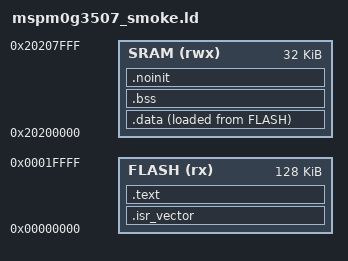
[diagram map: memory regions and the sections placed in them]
MEMORY
{
    FLASH (rx)  : ORIGIN = 0x00000000, LENGTH = 128K
    SRAM  (rwx) : ORIGIN = 0x20200000, LENGTH = 32K
}

_estack = ORIGIN(SRAM) + LENGTH(SRAM);

SECTIONS
{
    .isr_vector :
    {
        KEEP(*(.isr_vector))
    } > FLASH

    .text :
    {
        *(.text*)
        *(.rodata*)
        . = ALIGN(4);
    } > FLASH

    .data :
    {
        . = ALIGN(4);
        _sdata = .;
        *(.data*)
        . = ALIGN(4);
        _edata = .;
    } > SRAM AT > FLASH

    _sidata = LOADADDR(.data);

    .bss (NOLOAD) :
    {
        . = ALIGN(4);
        _sbss = .;
        *(.bss*)
        *(COMMON)
        . = ALIGN(4);
        _ebss = .;
    } > SRAM

    .noinit (NOLOAD) :
    {
        . = ALIGN(4);
        *(.noinit*)
        . = ALIGN(4);
    } > SRAM

    /DISCARD/ :
    {
        *(.ARM.exidx*)
        *(.ARM.extab*)
        *(.comment*)
        *(.note*)
    }
}
